VERSION "BMW i3 FlexRay custom draft v3"

NS_ :

BS_:

BU_: BMW_I3

CM_ "Draft DBC derived from BMW i3 FlexRay and PT-CAN logs. Address 27 was not observed in any uploaded segment. Signals below intentionally mix three classes: confirmed parse signals already used by CarState, state/proxy helpers useful for reverse engineering, and unresolved TX candidates kept for shadow-debug correlation.";

BO_ 21 LAT_STOCK_ANGLE_REQUEST_15: 17 BMW_I3
 SG_ LAT_STOCK_ANGLE_15_CYCLE_RAW : 0|8@1+ (1,0) [0|255] "" BMW_I3
 SG_ LAT_STOCK_ANGLE_15_WORD_1_2 : 8|16@1+ (1,0) [0|65535] "" BMW_I3
 SG_ LAT_STOCK_ANGLE_15_WORD_3_4 : 24|16@1+ (1,0) [0|65535] "" BMW_I3
 SG_ LAT_STOCK_ANGLE_15_WORD_5_6 : 40|16@1+ (1,0) [0|65535] "" BMW_I3
 SG_ LAT_STOCK_ANGLE_15_RAW : 56|16@1+ (1,0) [0|65535] "" BMW_I3
 SG_ LAT_STOCK_ANGLE_15_DEG_DRAFT : 56|16@1+ (0.011831,-387.55) [-720|720] "deg" BMW_I3
 SG_ LAT_STOCK_ANGLE_15_ICAN_48_OFFSET_TEST : 24|16@1+ (0.04395,-1098.75) [-720|720] "deg" BMW_I3
 SG_ LAT_STOCK_ANGLE_15_BRANCH_MARKER : 72|64@1+ (1,0) [0|18446744073709551615] "" BMW_I3
CM_ BO_ 21 "Stock angle-request candidate on the EDME-to-EPS side. Local route 58/59 analysis selects bytes 7..8 little-endian, not the I-CAN-hack 0x48 byte3..4 field: correlation against valid 0x33/src24 EPS angle is about +0.980 on route 58 and +0.929 on route 59. Treat only cycle byte0&0x3 == 0 or 2 plus bytes9..16 == FF as the real branch; the other branch is structural zero padding. Firmware TX is intentionally not enabled until the scheduler trigger is proven.";
CM_ SG_ 21 LAT_STOCK_ANGLE_15_RAW "Primary local angle-request candidate: raw = uint16_le(byte7, byte8). Observed near center around 32768; route-backed draft angle conversion is LAT_STOCK_ANGLE_15_DEG_DRAFT.";
CM_ SG_ 21 LAT_STOCK_ANGLE_15_DEG_DRAFT "Draft local fit from EDME/EPS routes 58 and 59 against valid 0x33 EPS_STEERING_ANGLE_BMW: angle_deg ~= raw * 0.011831 - 387.55. This is for analysis/openpilot target construction only and must be refined before closed-loop TX.";
CM_ SG_ 21 LAT_STOCK_ANGLE_15_ICAN_48_OFFSET_TEST "Reference-only I-CAN-hack 0x48 angle layout applied to 0x15 byte3..4. It is kept to compare against their formula, but local logs show byte7..8 is the stronger candidate.";
CM_ SG_ 21 LAT_STOCK_ANGLE_15_BRANCH_MARKER "Real 0x15 angle branch observed with bytes9..16 all 0xFF; zero branch must be ignored during correlation and TX reconstruction.";

BO_ 49 STEER_TORQUE: 17 BMW_I3
 SG_ STEER_TORQUE_CYCLE_RAW : 0|8@1+ (1,0) [0|255] "" BMW_I3
 SG_ STEER_TORQUE_RAW_WORD_A : 8|16@1+ (1,0) [0|65535] "" BMW_I3
 SG_ STEER_TORQUE_RAW_WORD_B : 24|16@1+ (1,0) [0|65535] "" BMW_I3
 SG_ STEER_TORQUE_RAW_WORD_C : 40|16@1+ (1,0) [0|65535] "" BMW_I3
 SG_ STEER_TORQUE_RAW_WORD_D : 56|16@1+ (1,0) [0|65535] "" BMW_I3
 SG_ DRIVER_STEER_TORQUE_BMW : 24|12@1+ (0.005,-10) [-10|10.475] "Nm" BMW_I3
 SG_ STEER_TORQUE_STATUS_RAW : 24|8@1+ (1,0) [0|255] "" BMW_I3
 CM_ BO_ 49 "Confirmed steering-torque helper. BMW-style driver torque lives in the 24|12 field and is valid on the cycle-0 subframe. CarState uses this path for steeringTorque/steeringPressed.";

BO_ 51 EPS_ANGLE: 17 BMW_I3
 SG_ EPS_ANGLE_CYCLE_RAW : 0|8@1+ (1,0) [0|255] "" BMW_I3
 SG_ EPS_ANGLE_RAW_WORD_A : 8|16@1+ (1,0) [0|65535] "" BMW_I3
 SG_ EPS_ANGLE_RAW_WORD_B : 24|16@1+ (1,0) [0|65535] "" BMW_I3
 SG_ EPS_ANGLE_RAW_WORD_C : 40|16@1+ (1,0) [0|65535] "" BMW_I3
 SG_ EPS_ANGLE_RAW_WORD_D : 56|16@1+ (1,0) [0|65535] "" BMW_I3
 SG_ EPS_STEERING_ANGLE_BMW : 24|16@1+ (0.042420980556,-1390.727380850223) [-465|465] "deg" BMW_I3
 CM_ BO_ 51 "FlexRay EPS angle frame. Raw steering angle lives in word B as bytes 3:4 little-endian and only the active subframes where byte0&0x3 is 0 or 2 carry angle content. Subframes 1 and 3 are structurally empty.";
CM_ SG_ 51 EPS_STEERING_ANGLE_BMW "Primary FlexRay EPS steering-angle candidate from raw word B at 24|16@1+ interpreted little-endian. Global refit against the legacy CAN steering angle on 0x302 across routes 0x401 and 0x402: angle_deg ~= raw_B * 0.042420980556 - 1390.727380850223. Apply only on active cycles 0/2; cycles 1/3 should be treated as empty subframes.";

BO_ 55 VEHICLE_SPEED_PROV: 17 BMW_I3
 SG_ VEHICLE_SPEED_CYCLE_RAW M : 0|2@1+ (1,0) [0|3] "" BMW_I3
 SG_ VEHICLE_SPEED_RAW_WORD_A : 8|16@1+ (1,0) [0|65535] "" BMW_I3
 SG_ VEHICLE_SPEED_RAW_WORD_B : 24|16@1+ (1,0) [0|65535] "" BMW_I3
 SG_ VEHICLE_SPEED_RAW_WORD_C : 40|16@1+ (1,0) [0|65535] "" BMW_I3
 SG_ VEHICLE_SPEED_RAW_WORD_D : 56|16@1+ (1,0) [0|65535] "" BMW_I3
 SG_ LONG_ACCEL_RAW m0 : 24|16@1+ (0.002,-65) [0|65535] "" BMW_I3
 SG_ VEHICLE_SPEED_BMW m3 : 24|16@1+ (0.015625,0) [0|65535] "kph" BMW_I3
 SG_ DRIVING_STATUS_BMW m3 : 44|2@1+ (1,0) [0|7] "" BMW_I3
CM_ BO_ 55 "Confirmed primary vehicle-speed source aligned with the BMW SP2018 multiplexed layout. CarState consumes the m3 vehicle-speed subframe directly for runtime vehicle speed.";

BO_ 56 DYNAMICS_YAW_PROV: 17 BMW_I3
 SG_ DYNAMICS_YAW_RAW_WORD_A : 8|16@1+ (1,0) [0|65535] "" BMW_I3
 SG_ DYNAMICS_YAW_RAW_WORD_B : 24|16@1+ (1,0) [0|65535] "" BMW_I3
 SG_ DYNAMICS_YAW_RAW_WORD_C : 40|16@1+ (1,0) [0|65535] "" BMW_I3
 SG_ DYNAMICS_YAW_RAW_WORD_D : 56|16@1+ (1,0) [0|65535] "" BMW_I3
 SG_ YAW_RATE_RAW_A : 8|16@1- (0.01,0) [-500|500] "deg/s" BMW_I3
 SG_ YAW_RATE_RAW_B : 24|16@1- (0.01,0) [-500|500] "deg/s" BMW_I3
 SG_ STEERING_ANGLE_PROXY_56_RAW : 88|16@1+ (1,0) [0|65535] "" BMW_I3
 SG_ STEERING_ANGLE_PROXY_56_DEG : 88|16@1+ (0.0260328634,-851.998806) [-720|720] "deg" BMW_I3
CM_ BO_ 56 "Confirmed vehicle-dynamics helper. Raw yaw fields remain useful for reverse-engineering and stock lateral comparison work. The late word at bytes 11..12 is kept only as a secondary steering-angle debug/support candidate now that frame 51 is promoted.";
CM_ SG_ 56 STEERING_ANGLE_PROXY_56_RAW "Secondary debug/support steering-angle proxy from route 00000402 fitting against PT-CAN 770. Keep for analysis only; no longer the primary steeringAngleDeg source.";
CM_ SG_ 56 STEERING_ANGLE_PROXY_56_DEG "Debug/support steering-angle estimate derived from STEERING_ANGLE_PROXY_56_RAW using the historical fit angle_deg ~= 0.0260328634 * raw56 - 851.998806. Not the primary steeringAngleDeg source anymore.";

BO_ 40 DRIVE_STATE: 17 BMW_I3
 SG_ DRIVE_STATE_CYCLE_COMPAT : 0|2@1+ (1,0) [0|3] "" BMW_I3
 SG_ DRIVE_STATE_RAW : 8|16@1+ (1,0) [0|65535] "" BMW_I3
  SG_ DRIVE_MODE_RAW : 24|8@1+ (1,0) [0|255] "" BMW_I3
 SG_ DRIVE_STATE_GEAR_M3_COMPAT : 24|4@1+ (1,0) [0|15] "" BMW_I3
 SG_ DRIVE_STATE_P_LOCKED_M3_COMPAT : 49|1@1+ (1,0) [0|1] "" BMW_I3
 SG_ DRIVE_STATE_KIND_BYTE_11 : 88|8@1+ (1,0) [0|255] "" BMW_I3
 SG_ DRIVE_STATE_KIND_BYTE_14 : 112|8@1+ (1,0) [0|255] "" BMW_I3
CM_ BO_ 40 "Production drive-state frame. Cross-check against dynm BMW SP2018 FlexRay DBC shows this frame is the closest local match to their maybe_gear_switch frame, and current i3 routes support using its cycle_count plus the byte-11/byte-14 discriminator path as the primary FlexRay gear source in CarState.";

BO_ 44 LAT_STOCK_TORQUE_CONTROL_44: 17 BMW_I3
 SG_ LAT_STOCK_TORQUE_44_CYCLE_COUNT : 7|8@0+ (1,0) [0|255] "" BMW_I3
 SG_ LAT_STOCK_TORQUE_44_CHECKSUM_1 : 15|8@0+ (1,0) [0|255] "" BMW_I3
 SG_ LAT_STOCK_TORQUE_44_COUNTER_1 : 19|4@0+ (1,0) [0|15] "" BMW_I3
 SG_ LAT_STOCK_TORQUE_44_CONST_F_1 : 23|4@0+ (1,0) [0|15] "" BMW_I3
 SG_ LAT_STOCK_TORQUE_44_CONST_D0 : 31|8@0+ (1,0) [0|255] "" BMW_I3
 SG_ LAT_STOCK_TORQUE_44_CONST_E7 : 39|8@0+ (1,0) [0|255] "" BMW_I3
 SG_ LAT_STOCK_TORQUE_44_BYTE_5_BE : 47|8@0+ (1,0) [0|255] "" BMW_I3
 SG_ LAT_STOCK_TORQUE_44_BYTE_6 : 48|8@1+ (1,0) [0|255] "" BMW_I3
 SG_ LAT_STOCK_TORQUE_44_NIBBLE_7 : 59|4@0+ (1,0) [0|7] "" BMW_I3
 SG_ LAT_STOCK_TORQUE_44_MODE : 67|4@0+ (1,0) [0|15] "" BMW_I3
 SG_ LAT_STOCK_TORQUE_44_REQUEST_1 : 68|1@0+ (1,0) [0|1] "" BMW_I3
 SG_ LAT_STOCK_TORQUE_44_CHECKSUM_2 : 79|8@0+ (1,0) [0|255] "" BMW_I3
 SG_ LAT_STOCK_TORQUE_44_COUNTER_2 : 83|4@0+ (1,0) [0|15] "" BMW_I3
 SG_ LAT_STOCK_TORQUE_44_CONST_F_2 : 87|4@0+ (1,0) [0|15] "" BMW_I3
 SG_ LAT_STOCK_TORQUE_44_RAW : 104|16@1- (1,0) [-32768|32767] "" BMW_I3
 SG_ LAT_STOCK_TORQUE_44_ALT_WORD_10_11 : 80|16@1+ (1,0) [0|65535] "" BMW_I3
 SG_ LAT_STOCK_TORQUE_44_ALT_WORD_12_13 : 96|16@1- (1,0) [-32768|32767] "" BMW_I3
 SG_ LAT_STOCK_TORQUE_44_ALT_WORD_14_15 : 112|16@1- (1,0) [-32768|32767] "" BMW_I3
 SG_ LAT_STOCK_TORQUE_44_ICAN_HACK_NM : 88|12@1+ (0.005,-10) [-10|10.475] "Nm" BMW_I3
 SG_ LAT_STOCK_TORQUE_44_MODE_COPY : 103|4@0+ (1,0) [0|15] "" BMW_I3
 SG_ LAT_STOCK_TORQUE_44_CONST_FF_1 : 111|8@0+ (1,0) [0|255] "" BMW_I3
 SG_ LAT_STOCK_TORQUE_44_CONST_FF_2 : 119|8@0+ (1,0) [0|255] "" BMW_I3
 SG_ LAT_STOCK_TORQUE_44_CONST_F_3 : 123|4@0+ (1,0) [0|15] "" BMW_I3
 SG_ LAT_STOCK_TORQUE_44_REQUEST_2 : 125|2@0+ (1,0) [0|3] "" BMW_I3
 SG_ LAT_STOCK_TORQUE_44_LKA_STATE : 131|4@0+ (1,0) [0|15] "" BMW_I3
 SG_ LAT_STOCK_TORQUE_44_REQUEST_3 : 132|1@0+ (1,0) [0|1] "" BMW_I3
CM_ BO_ 44 "Stock lateral torque/control candidate on the vehicle-side companion stream. Route 58/59 TJA-window analysis points to bytes 13..14 signed little-endian as the strongest local equivalent to 0x33/src1 steering output. Firmware injection follows the I-CAN-hack raw override model: trigger 0x42, target 0x44, cycle mask 0x01, base 0, copy payload bytes 1..16, direction FR3, then update only the FlexRay header cycle/count CRC. Host/openpilot must compute payload CRCs byte1=crc8(byte2..8, init 0xA4) and byte9=crc8(byte10..16, init 0xDC).";
CM_ SG_ 44 LAT_STOCK_TORQUE_44_RAW "Primary local torque/control-like value: raw = int16_le(byte13, byte14). Correlation against 0x33/src1 bytes 3..4 inside managed TJA windows was about +0.847 on route 58 and +0.916 on route 59.";
CM_ SG_ 44 LAT_STOCK_TORQUE_44_ALT_WORD_10_11 "Secondary debug word from bytes 10..11. Keep only for comparison while reconstructing the full 0x44 payload.";
CM_ SG_ 44 LAT_STOCK_TORQUE_44_ALT_WORD_12_13 "Secondary debug word from bytes 12..13. It correlates less consistently than bytes 13..14 and is not the selected torque value.";
CM_ SG_ 44 LAT_STOCK_TORQUE_44_ALT_WORD_14_15 "Secondary debug word from bytes 14..15. Keep only for comparison while reconstructing the full 0x44 payload.";
CM_ SG_ 44 LAT_STOCK_TORQUE_44_ICAN_HACK_NM "Reference layout from I-CAN-hack pico-flexray 0x44 EPS_CONTROL torque field: 12-bit unsigned at byte11/bit88, factor 0.005, offset -10 Nm. Included as a cross-check, not selected over the local b13..14 route fit.";
CM_ SG_ 44 LAT_STOCK_TORQUE_44_CHECKSUM_1 "Application CRC for the first 0x44 payload block. Host must set this to crc8(payload bytes 2..8, init 0xA4); firmware raw override does not recalculate it.";
CM_ SG_ 44 LAT_STOCK_TORQUE_44_CHECKSUM_2 "Application CRC for the second 0x44 payload block. Host must set this to crc8(payload bytes 10..16, init 0xDC); firmware raw override does not recalculate it.";
CM_ SG_ 44 LAT_STOCK_TORQUE_44_MODE "I-CAN-hack EPS_CONTROL torque mode field. Their script uses 2 when active, mostly 14 otherwise.";
CM_ SG_ 44 LAT_STOCK_TORQUE_44_MODE_COPY "Mirror of LAT_STOCK_TORQUE_44_MODE in the I-CAN-hack EPS_CONTROL layout.";
CM_ SG_ 44 LAT_STOCK_TORQUE_44_LKA_STATE "I-CAN-hack EPS_CONTROL LKA state field. Observed/scripted behavior ramps through 0..14 on engage/disengage and typically stays around 5..9 while active.";
CM_ SG_ 44 LAT_STOCK_TORQUE_44_REQUEST_2 "I-CAN-hack EPS_CONTROL request state: 1 inactive, 2 active.";
CM_ SG_ 44 LAT_STOCK_TORQUE_44_REQUEST_3 "I-CAN-hack EPS_CONTROL request bit. Their script sets it to 1 only while not ramping up/down and active.";
VAL_ 44 LAT_STOCK_TORQUE_44_REQUEST_2 1 "INACTIVE" 2 "ACTIVE";

BO_ 60 LAT_STOCK_TX_TRIGGER_CANDIDATE: 17 BMW_I3
 SG_ LAT_STOCK_TRIGGER_PHASE_BYTE_0 : 0|8@1+ (1,0) [0|255] "" BMW_I3
 SG_ LAT_STOCK_TRIGGER_SUBFRAME_LSB : 0|2@1+ (1,0) [0|3] "" BMW_I3
 SG_ LAT_STOCK_TRIGGER_CMD_PHASE : 1|5@1+ (1,0) [0|31] "" BMW_I3
CM_ BO_ 60 "Primary SAS-side predecessor/trigger for the stock lateral burst on the i3. Latest route work now treats frame 96 as the active payload candidate. Frame 60 itself remains structurally near-empty outside byte0, so treat it as the scheduler/trigger half of the burst rather than the analog steering payload.";
CM_ SG_ 60 LAT_STOCK_TRIGGER_PHASE_BYTE_0 "Raw scheduler byte for the SAS-side lateral burst. This remains the practical trigger byte for firmware-aligned injection work.";
CM_ SG_ 60 LAT_STOCK_TRIGGER_SUBFRAME_LSB "Low two bits of frame-60 byte0. Useful when reconstructing the four-subframe burst order observed in the SAS 20 ms lateral scheduler.";
CM_ SG_ 60 LAT_STOCK_TRIGGER_CMD_PHASE "Derived command-phase view of frame-60 byte0 (byte0 >> 1). Keep as a coarse scheduler helper while the real command stays phase-local on frame 96.";

BO_ 72 LAT_STOCK_FRAME_72_CANDIDATE: 17 BMW_I3
 SG_ LAT_STOCK_72_BYTE_0 : 0|8@1+ (1,0) [0|255] "" BMW_I3
 SG_ LAT_STOCK_72_CYCLE_COUNT : 0|8@1+ (1,0) [0|255] "" BMW_I3
 SG_ LAT_STOCK_72_BYTE_1 : 8|8@1+ (1,0) [0|255] "" BMW_I3
 SG_ LAT_STOCK_72_CRC1 : 8|8@1+ (1,0) [0|255] "" BMW_I3
 SG_ LAT_STOCK_72_BYTE_2 : 16|8@1+ (1,0) [0|255] "" BMW_I3
 SG_ LAT_STOCK_72_CNT1 : 20|4@1+ (1,0) [0|15] "" BMW_I3
 SG_ LAT_STOCK_72_ALWAYS_0X9 : 16|4@1+ (1,0) [0|15] "" BMW_I3
 SG_ LAT_STOCK_72_BYTE_3 : 24|8@1+ (1,0) [0|255] "" BMW_I3
 SG_ LAT_STOCK_72_BYTE_4 : 32|8@1+ (1,0) [0|255] "" BMW_I3
 SG_ LAT_STOCK_72_STEERING_ANGLE_REQ : 24|16@1+ (1,0) [0|65535] "" BMW_I3
 SG_ LAT_STOCK_72_BYTE_5 : 40|8@1+ (1,0) [0|255] "" BMW_I3
 SG_ LAT_STOCK_72_BYTE_6 : 48|8@1+ (1,0) [0|255] "" BMW_I3
 SG_ LAT_STOCK_72_STEER_TORQUE_REQ : 40|16@1+ (1,0) [0|65535] "" BMW_I3
 SG_ LAT_STOCK_72_BYTE_7 : 56|8@1+ (1,0) [0|255] "" BMW_I3
 SG_ LAT_STOCK_72_TJA_READY : 56|8@1+ (1,0) [0|255] "" BMW_I3
 SG_ LAT_STOCK_72_BYTE_8 : 64|8@1+ (1,0) [0|255] "" BMW_I3
 SG_ LAT_STOCK_72_ASSIST_MODE : 64|8@1+ (1,0) [0|255] "" BMW_I3
 SG_ LAT_STOCK_72_BYTE_9 : 72|8@1+ (1,0) [0|255] "" BMW_I3
 SG_ LAT_STOCK_72_WAYBACK_EN1_LANE_KEEPING_TRIGGER : 72|8@1+ (1,0) [0|255] "" BMW_I3
 SG_ LAT_STOCK_72_BYTE_10 : 80|8@1+ (1,0) [0|255] "" BMW_I3
 SG_ LAT_STOCK_72_LANE_KEEPING_TRIGGERED : 80|8@1+ (1,0) [0|255] "" BMW_I3
 SG_ LAT_STOCK_72_BYTE_11 : 88|8@1+ (1,0) [0|255] "" BMW_I3
 SG_ LAT_STOCK_72_LIKE_ASSIST_TORQUE_RESERVE : 88|8@1+ (1,0) [0|255] "" BMW_I3
 SG_ LAT_STOCK_72_BYTE_12 : 96|8@1+ (1,0) [0|255] "" BMW_I3
 SG_ LAT_STOCK_72_BYTE_13 : 104|8@1+ (1,0) [0|255] "" BMW_I3
 SG_ LAT_STOCK_72_BYTE_14 : 112|8@1+ (1,0) [0|255] "" BMW_I3
 SG_ LAT_STOCK_72_CONSTANTS : 96|26@1+ (1,0) [0|262143] "" BMW_I3
 SG_ LAT_STOCK_72_WAYBACK_EN_2 : 114|2@1+ (1,0) [0|3] "" BMW_I3
 SG_ LAT_STOCK_72_STEERING_ENGAGED : 116|4@1+ (1,0) [0|15] "" BMW_I3
 SG_ LAT_STOCK_72_BYTE_15 : 120|8@1+ (1,0) [0|255] "" BMW_I3
 SG_ LAT_STOCK_72_BYTE_16 : 128|8@1+ (1,0) [0|255] "" BMW_I3
CM_ BO_ 72 "Raw stock frame-72 candidate, reintroduced for parameter-by-parameter comparison against the SP2018 72-byte layout. Current fixed synthetic blocks: cycle_count = 0x00, crc1 = 0x00 with real final CRC to be computed later outside the DBC, cnt1 = 0x00, always_0x9 placeholder = 0xF, steering_angle_req placeholder = 0x0000, steer_torque_req placeholder = 0xFFFF, TJA_ready placeholder = 0xFF, assist_mode placeholder = 0xE0, wayback_en1_lane_keeping_trigger placeholder = 0xFF, lane_keeping_triggered placeholder = 0xFF, like_assist_torque_reserve placeholder = 0xFF, constants placeholder = 0x3FFFF, wayback_en_2 placeholder = 0x3, steering_engaged placeholder = 0xF. For blocks 3-14, firmware currently preserves the live OEM payload bytes from the cached 72 template.";
CM_ SG_ 72 LAT_STOCK_72_CYCLE_COUNT "Block 1 candidate on local frame 72. Current synthetic decision: use a fixed value of 0x00 when building a local 72 frame, matching the simpler dynm-style approach instead of waiting on OEM live timing.";
CM_ SG_ 72 LAT_STOCK_72_CRC1 "Block 2 candidate on local frame 72. Current synthetic decision: keep this DBC-visible crc1 field at 0x00 and compute any real final CRC later outside the DBC, dynm-style.";
CM_ SG_ 72 LAT_STOCK_72_CNT1 "Block 3 candidate on local frame 72 in the same positional slot as SP2018 cnt1. Current synthetic decision: fix it to 0x00, matching SMNOGAR/dynm builder behavior.";
CM_ SG_ 72 LAT_STOCK_72_ALWAYS_0X9 "Block 4 candidate on local frame 72 in the same positional slot as SP2018 always_0x9. Placeholder decision in DBC/controller: set to 0xF if synthesized locally. Firmware currently preserves the live OEM high nibble of byte2 from the cached 72 template, so the placeholder is not the final bus value.";
CM_ SG_ 72 LAT_STOCK_72_STEERING_ANGLE_REQ "Block 5 candidate in the same positional slot as SP2018 steering_angle_req. Placeholder decision in DBC/controller: set to 0x0000 if synthesized locally. Firmware currently preserves the live OEM bytes 3:4 from the cached 72 template, so this placeholder is not the final bus value.";
CM_ SG_ 72 LAT_STOCK_72_STEER_TORQUE_REQ "Block 6 candidate in the same positional slot as SP2018 steer_torque_req. Placeholder decision in DBC/controller: set to 0xFFFF if synthesized locally. Firmware currently preserves the live OEM bytes 5:6 from the cached 72 template, so this placeholder is not the final bus value.";
CM_ SG_ 72 LAT_STOCK_72_TJA_READY "Block 7 candidate in the same positional slot as SP2018 TJA_ready. Placeholder decision in DBC/controller: set to 0xFF if synthesized locally. Firmware currently preserves the live OEM byte7 from the cached 72 template, so this placeholder is not the final bus value.";
CM_ SG_ 72 LAT_STOCK_72_ASSIST_MODE "Block 8 candidate in the same positional slot as SP2018 assist_mode. Placeholder decision in DBC/controller: set to 0xE0 if synthesized locally. Firmware currently preserves the live OEM byte8 from the cached 72 template, so this placeholder is not the final bus value.";
CM_ SG_ 72 LAT_STOCK_72_WAYBACK_EN1_LANE_KEEPING_TRIGGER "Block 9 candidate in the same positional slot as SP2018 wayback_en1_lane_keeping_trigger. Placeholder decision in DBC/controller: set to 0xFF if synthesized locally. Firmware currently preserves the live OEM byte9 from the cached 72 template, so this placeholder is not the final bus value.";
CM_ SG_ 72 LAT_STOCK_72_LANE_KEEPING_TRIGGERED "Block 10 candidate in the same positional slot as SP2018 lane_keeping_triggered. Placeholder decision in DBC/controller: set to 0xFF if synthesized locally. Firmware currently preserves the live OEM byte10 from the cached 72 template, so this placeholder is not the final bus value.";
CM_ SG_ 72 LAT_STOCK_72_LIKE_ASSIST_TORQUE_RESERVE "Block 11 candidate in the same positional slot as SP2018 like_assist_torque_reserve. Placeholder decision in DBC/controller: set to 0xFF if synthesized locally. Firmware currently preserves the live OEM byte11 from the cached 72 template, so this placeholder is not the final bus value.";
CM_ SG_ 72 LAT_STOCK_72_CONSTANTS "Block 12 candidate in the same positional slot as SP2018 constants. Placeholder decision in DBC/controller: set to 0x3FFFF if synthesized locally. Firmware currently preserves the live OEM bytes 12:14 (including the low 2 bits of byte14) from the cached 72 template, so this placeholder is not the final bus value.";
CM_ SG_ 72 LAT_STOCK_72_WAYBACK_EN_2 "Block 13 candidate in the same positional slot as SP2018 wayback_en_2. Placeholder decision in DBC/controller: set to 0x3 if synthesized locally. Firmware already preserves the live OEM byte14 from the cached 72 template, so this placeholder is not the final bus value.";
CM_ SG_ 72 LAT_STOCK_72_STEERING_ENGAGED "Block 14 candidate in the same positional slot as SP2018 steering_engaged. Placeholder decision in DBC/controller: set to 0xF if synthesized locally. Firmware already preserves the live OEM byte14 from the cached 72 template, so this placeholder is not the final bus value.";

BO_ 43 CHASSIS_STATE_CANDIDATE: 17 BMW_I3
 SG_ CHASSIS_STATE_A : 8|16@1+ (1,0) [0|65535] "" BMW_I3
 SG_ CHASSIS_STATE_B : 24|16@1+ (1,0) [0|65535] "" BMW_I3
 CM_ SG_ 43 CHASSIS_STATE_A "Experimental secondary dynamic-state frame. It follows some longitudinal phase changes, but remains too weak and indirect for stock command use.";

BO_ 63 LONG_STATE_HELPER_D: 17 BMW_I3
 SG_ LONG_STATE_HELPER_D_WORD_A : 8|16@1+ (1,0) [0|65535] "" BMW_I3
 SG_ LONG_STATE_HELPER_D_WORD_B : 24|16@1+ (1,0) [0|65535] "" BMW_I3
 SG_ LONG_STATE_HELPER_D_WORD_C : 40|16@1+ (1,0) [0|65535] "" BMW_I3
 SG_ LONG_STATE_HELPER_D_WORD_D : 56|16@1+ (1,0) [0|65535] "" BMW_I3
 CM_ BO_ 63 "Raw helper frame for longitudinal state closure. Keep read-only; do not treat as a direct accel command.";

BO_ 93 ACC_TJA_OLD_ROUTE_HELPER_A: 17 BMW_I3
 SG_ ACC_TJA_OLD_A_CYCLE : 0|8@1+ (1,0) [0|255] "" BMW_I3
 SG_ LONG_STATE_HELPER_A_WORD_A : 8|16@1+ (1,0) [0|65535] "" BMW_I3
 SG_ LONG_STATE_HELPER_A_WORD_B : 24|16@1+ (1,0) [0|65535] "" BMW_I3
 SG_ LONG_STATE_HELPER_A_WORD_C : 40|16@1+ (1,0) [0|65535] "" BMW_I3
 SG_ LONG_STATE_HELPER_A_WORD_D : 56|16@1+ (1,0) [0|65535] "" BMW_I3
 SG_ ACC_TJA_OLD_A_WORD_A : 8|16@1+ (1,0) [0|65535] "" BMW_I3
 SG_ ACC_TJA_OLD_A_WORD_B : 24|16@1+ (1,0) [0|65535] "" BMW_I3
 SG_ ACC_TJA_OLD_A_WORD_C : 40|16@1+ (1,0) [0|65535] "" BMW_I3
 SG_ ACC_TJA_OLD_A_WORD_D : 56|16@1+ (1,0) [0|65535] "" BMW_I3
 SG_ ACC_TJA_OLD_STATE_MAIN_A : 40|16@1+ (1,0) [0|65535] "" BMW_I3
 CM_ BO_ 93 "Experimental helper from legacy multi-segment TJA routes 00000054/55/56. This src23 frame repeatedly changed around ACC/TJA/stalk command windows and is kept as a raw helper only for old-route correlation.";

BO_ 97 ACC_TJA_OLD_ROUTE_HELPER_B: 17 BMW_I3
 SG_ ACC_TJA_OLD_B_CYCLE : 0|8@1+ (1,0) [0|255] "" BMW_I3
 SG_ ACC_TJA_OLD_B_WORD_A : 8|16@1+ (1,0) [0|65535] "" BMW_I3
 SG_ ACC_TJA_OLD_B_WORD_B : 24|16@1+ (1,0) [0|65535] "" BMW_I3
 SG_ ACC_TJA_OLD_B_WORD_C : 40|16@1+ (1,0) [0|65535] "" BMW_I3
 SG_ ACC_TJA_OLD_B_WORD_D : 56|16@1+ (1,0) [0|65535] "" BMW_I3
 SG_ ACC_TJA_OLD_STALK_MAIN_A : 8|16@1+ (1,0) [0|65535] "" BMW_I3
 SG_ ACC_TJA_OLD_STALK_MAIN_B : 24|16@1+ (1,0) [0|65535] "" BMW_I3
 CM_ BO_ 97 "Experimental helper from legacy multi-segment TJA routes 00000054/55/56. This src23 frame is one of the strongest recurring candidates for ACC/TJA/stalk command state and is exposed raw for old-route analysis.";

BO_ 102 COLUMN_SWITCH_CANDIDATE: 17 BMW_I3
 SG_ COLUMN_SWITCH_WORD_A : 8|16@1+ (1,0) [0|65535] "" BMW_I3
 SG_ COLUMN_SWITCH_WORD_B : 24|16@1+ (1,0) [0|65535] "" BMW_I3
 SG_ COLUMN_SWITCH_WORD_C : 40|16@1+ (1,0) [0|65535] "" BMW_I3
 SG_ COLUMN_SWITCH_WORD_D : 56|16@1+ (1,0) [0|65535] "" BMW_I3
 CM_ BO_ 102 "Experimental column-switch / indicator candidate. In the parked command-isolation route, this frame changed clearly during right/left indicator windows and also moved with some ACC/TJA button presses. Treat as a likely steering-column input frame rather than pure ADAS state.";

BO_ 110 ACC_TJA_OLD_ROUTE_HELPER_C: 17 BMW_I3
 SG_ ACC_TJA_OLD_C_CYCLE : 0|8@1+ (1,0) [0|255] "" BMW_I3
 SG_ ACC_TJA_OLD_C_WORD_A : 8|16@1+ (1,0) [0|65535] "" BMW_I3
 SG_ ACC_TJA_OLD_C_WORD_B : 24|16@1+ (1,0) [0|65535] "" BMW_I3
 SG_ ACC_TJA_OLD_C_WORD_C : 40|16@1+ (1,0) [0|65535] "" BMW_I3
 SG_ ACC_TJA_OLD_C_WORD_D : 56|16@1+ (1,0) [0|65535] "" BMW_I3
 CM_ BO_ 110 "Experimental helper from legacy multi-segment TJA routes 00000054/55/56. This src23 frame moved with speed-stalk and ACC transitions often enough to warrant a raw helper block.";

BO_ 106 ACC_STALK_TJA_CANDIDATE_A: 17 BMW_I3
 SG_ ACC_STALK_TJA_WORD_A : 8|16@1+ (1,0) [0|65535] "" BMW_I3
 SG_ ACC_STALK_TJA_WORD_B : 24|16@1+ (1,0) [0|65535] "" BMW_I3
 SG_ ACC_STALK_TJA_WORD_C : 40|16@1+ (1,0) [0|65535] "" BMW_I3
 SG_ ACC_STALK_TJA_WORD_D : 56|16@1+ (1,0) [0|65535] "" BMW_I3
 CM_ BO_ 106 "Experimental ACC/TJA candidate from TJA and parked command-isolation routes. Changed coherently around SET, RES, ACC, TJA, speed-stalk increment/decrement, distance-button, and ACC off windows. Byte pair around bits 24..39 stayed stable enough for comparison across sessions, but no clean bit-level interpretation is confirmed yet.";

BO_ 112 ACC_STALK_TJA_CANDIDATE_B: 17 BMW_I3
 SG_ ACC_STALK_TJA_B_WORD_A : 8|16@1+ (1,0) [0|65535] "" BMW_I3
 SG_ ACC_STALK_TJA_B_WORD_B : 24|16@1+ (1,0) [0|65535] "" BMW_I3
 SG_ ACC_STALK_TJA_B_WORD_C : 40|16@1+ (1,0) [0|65535] "" BMW_I3
 SG_ ACC_STALK_TJA_B_WORD_D : 56|16@1+ (1,0) [0|65535] "" BMW_I3
 SG_ LAT_STOCK_MAIN_BYTE_0 : 0|8@1+ (1,0) [0|255] "" BMW_I3
 SG_ LAT_STOCK_MAIN_BYTE_1 : 8|8@1+ (1,0) [0|255] "" BMW_I3
 SG_ LAT_STOCK_MAIN_WORD_A : 8|16@1+ (1,0) [0|65535] "" BMW_I3
 SG_ LAT_STOCK_MAIN_WORD_B : 24|16@1+ (1,0) [0|65535] "" BMW_I3
 SG_ LAT_STOCK_MAIN_WORD_C : 40|16@1+ (1,0) [0|65535] "" BMW_I3
 SG_ LAT_STOCK_MAIN_WORD_D : 56|16@1+ (1,0) [0|65535] "" BMW_I3
 SG_ LAT_STOCK_MAIN_BYTE_5 : 40|8@1+ (1,0) [0|255] "" BMW_I3
 SG_ LAT_STOCK_ACTIVE_HINT : 45|1@1+ (1,0) [0|1] "" BMW_I3
CM_ BO_ 112 "Primary lateral RX/state helper. Confirmed on historical routes 00000054 and 00000055 and reinforced by managed-TJA route 00000176. Historical logs exposed it on src24; modern dual-FlexRay logging exposes the same frame on src1. It changes cleanly between manual driving, ACC-base, and TJA-assisted steering windows and is the best current candidate for reverse-engineering stock lateral control state/content. Byte5 bit5 is the strongest live discriminator: off/manual tends to set the bit, assisted steering tends to clear it. CarState now uses this as the live stock_lat_active_hint gate before trusting the phase-local 96 direction hint.";
CM_ SG_ 112 LAT_STOCK_MAIN_BYTE_5 "Best current live assisted-steering state discriminator. Bit5 set tends to mean manual/off; bit5 clear tends to mean assisted/TJA-active. CarState uses this to gate the phase-local 96 direction hint.";
CM_ SG_ 112 LAT_STOCK_ACTIVE_HINT "Derived boolean helper from LAT_STOCK_MAIN_BYTE_5 bit5. 1 means the stock lateral system appears active enough to trust 96 direction hints; 0 means suppress direction to unknown.";

BO_ 116 ACC_STALK_TJA_CANDIDATE_C: 17 BMW_I3
 SG_ ACC_STALK_TJA_C_WORD_A : 8|16@1+ (1,0) [0|65535] "" BMW_I3
 SG_ ACC_STALK_TJA_C_WORD_B : 24|16@1+ (1,0) [0|65535] "" BMW_I3
 SG_ ACC_STALK_TJA_C_WORD_C : 40|16@1+ (1,0) [0|65535] "" BMW_I3
 SG_ ACC_STALK_TJA_C_WORD_D : 56|16@1+ (1,0) [0|65535] "" BMW_I3
 SG_ LAT_STOCK_SUPPORT_WORD_A : 8|16@1+ (1,0) [0|65535] "" BMW_I3
 SG_ LAT_STOCK_SUPPORT_WORD_B : 24|16@1+ (1,0) [0|65535] "" BMW_I3
 SG_ LAT_STOCK_SUPPORT_WORD_C : 40|16@1+ (1,0) [0|65535] "" BMW_I3
 SG_ LAT_STOCK_SUPPORT_WORD_D : 56|16@1+ (1,0) [0|65535] "" BMW_I3
 SG_ LAT_STOCK_SUPPORT_BYTE_1 : 8|8@1+ (1,0) [0|255] "" BMW_I3
 SG_ LAT_STOCK_SUPPORT_BYTE_2 : 16|8@1+ (1,0) [0|255] "" BMW_I3
 SG_ LAT_STOCK_SUPPORT_BYTE_5 : 40|8@1+ (1,0) [0|255] "" BMW_I3
CM_ BO_ 116 "Secondary lateral RX/state helper. Confirmed on historical routes 00000054 and 00000055, present on the modern interface in route 000000b3, and strengthened by managed-TJA route 00000176. Historical logs exposed it on src23; modern dual-FlexRay logging exposes the same frame on src1. It tracks the same assisted-steering phases as 112 and is the best current secondary helper for stock lateral command/echo analysis. Byte5 is not yet a standalone boolean, but it moves through stable phase families alongside 112 and is logged as support evidence for the live stock_lat_active_hint path.";
CM_ SG_ 116 LAT_STOCK_SUPPORT_BYTE_5 "Secondary state-support byte for stock lateral activity. Not yet a standalone boolean, but it moves through stable phase families alongside frame 112 and is useful as corroborating evidence when validating assisted-steering windows.";

BO_ 124 ACC_STALK_TJA_CANDIDATE_D: 17 BMW_I3
 SG_ ACC_STALK_TJA_D_WORD_A : 8|16@1+ (1,0) [0|65535] "" BMW_I3
 SG_ ACC_STALK_TJA_D_WORD_B : 24|16@1+ (1,0) [0|65535] "" BMW_I3
 SG_ ACC_STALK_TJA_D_WORD_C : 40|16@1+ (1,0) [0|65535] "" BMW_I3
 SG_ ACC_STALK_TJA_D_WORD_D : 56|16@1+ (1,0) [0|65535] "" BMW_I3
 CM_ BO_ 124 "Experimental ACC/TJA candidate from TJA and parked command-isolation routes. Strongly correlated with SET, RES, ACC, TJA, speed-stalk increment/decrement, distance-button, and ACC off. This frame is a priority candidate for future bit-level extraction of ACC/TJA state.";

BO_ 131 LAT_TJA_COMMAND_CANDIDATE: 17 BMW_I3
 SG_ LAT_TJA_CYCLE : 0|8@1+ (1,0) [0|255] "" BMW_I3
 SG_ LAT_TJA_BYTE_1 : 8|8@1+ (1,0) [0|255] "" BMW_I3
 SG_ LAT_TJA_BYTE_2 : 16|8@1+ (1,0) [0|255] "" BMW_I3
 SG_ LAT_TJA_BYTE_3 : 24|8@1+ (1,0) [0|255] "" BMW_I3
 SG_ LAT_TJA_BYTE_4 : 32|8@1+ (1,0) [0|255] "" BMW_I3
 SG_ LONG_TARGET_U_83 : 24|16@1+ (1,0) [0|65535] "" BMW_I3
 SG_ LONG_TARGET_SPEED_EST_83 : 24|16@1+ (0.047815,-1460.510) [0|300] "kph" BMW_I3
 SG_ LAT_TJA_BYTE_5 : 40|8@1+ (1,0) [0|255] "" BMW_I3
 SG_ LAT_TJA_BYTE_6 : 48|8@1+ (1,0) [0|255] "" BMW_I3
 SG_ LAT_TJA_BYTE_7 : 56|8@1+ (1,0) [0|255] "" BMW_I3
 SG_ LAT_TJA_BYTE_8 : 64|8@1+ (1,0) [0|255] "" BMW_I3
 SG_ LAT_TJA_GATE_BYTE_5 : 40|8@1+ (1,0) [0|255] "" BMW_I3
 SG_ LAT_TJA_GATE_BYTE_6 : 48|8@1+ (1,0) [0|255] "" BMW_I3
 SG_ LAT_TJA_GATE_VALID : 46|1@1+ (1,0) [0|1] "" BMW_I3
 SG_ LAT_TJA_DIR_RULE_B1 : 8|8@1+ (1,0) [0|255] "" BMW_I3
 SG_ LAT_TJA_DIR_RULE_B3 : 24|8@1+ (1,0) [0|255] "" BMW_I3
CM_ BO_ 131 "Mixed stock ADAS state/command frame on src0. Current route-backed work treats bytes 3:4 little-endian as the active stock longitudinal target-like field, not as a lateral-angle request. Bytes0/1/2/7/8 are live OEM structural or coded bytes and should be copied through from the real bus template. Bytes5/6 should normally be sent from the host as the active gate 0x80/0x02. Within the managed longitudinal branch, byte3 behaves like an analog modular value, byte4 counts byte3 wrap events, and the combined word at bytes 3:4 little-endian gives the best current stock-compatible target-speed-like value u = byte3 + 256*byte4. Byte1 remains unresolved and should currently be preserved from the OEM frame rather than synthesized.";
CM_ SG_ 131 LAT_TJA_CYCLE "Live OEM cycle/phase byte. Do not synthesize a static value; copy it from the cached real-bus 0x83 template before injection.";
CM_ SG_ 131 LAT_TJA_BYTE_1 "Live OEM unresolved coded byte. Current analysis does not support treating it as analog steering or a simple CRC/checksum, so preserve it from the cached real-bus 0x83 template before injection.";
CM_ SG_ 131 LAT_TJA_BYTE_2 "Live OEM cyclic byte. In active TJA it rolls 0xF0..0xFE with no observed exceptions on validated routes; copy it from the cached real-bus 0x83 template before injection.";
CM_ SG_ 131 LAT_TJA_BYTE_3 "Current best analog stock longitudinal candidate. Treat this as the low byte of the internal target-speed-like value only when paired with LAT_TJA_BYTE_4.";
CM_ SG_ 131 LAT_TJA_BYTE_4 "Slow wrap counter for LAT_TJA_BYTE_3. It increments on byte3 high-to-low wraps (255->0) and decrements on low-to-high wraps (0->255), giving u = byte3 + 256*byte4.";
CM_ SG_ 131 LONG_TARGET_U_83 "Debug-only stock longitudinal target-like value reconstructed as bytes 3:4 little-endian, i.e. u = byte3 + 256*byte4.";
CM_ SG_ 131 LONG_TARGET_SPEED_EST_83 "Debug-only speed estimate from LONG_TARGET_U_83 using the current best cross-route-compatible fit target_speed_kph ~= 0.047815 * u - 1460.510. Use for analysis only, not as a safety-critical actuation law.";
CM_ SG_ 131 LAT_TJA_BYTE_7 "Live OEM structural byte. Do not synthesize a static value; copy it from the cached real-bus 0x83 template before injection.";
CM_ SG_ 131 LAT_TJA_BYTE_8 "Live OEM structural byte. Do not synthesize a static value; copy it from the cached real-bus 0x83 template before injection.";
CM_ SG_ 131 LAT_TJA_GATE_BYTE_5 "Active TJA gate byte. Default host value should be 0x80.";
CM_ SG_ 131 LAT_TJA_GATE_BYTE_6 "Active TJA gate byte. Default host value should be 0x02.";
CM_ SG_ 131 LAT_TJA_GATE_VALID "Debug helper: true when byte5=0x80 and byte6=0x02.";
VAL_ 131 LAT_TJA_GATE_BYTE_5 0 "OFF_GATE" 128 "TJA_ACTIVE_DEFAULT" 131 "ALT_ACTIVE_401_ONLY";
VAL_ 131 LAT_TJA_GATE_BYTE_6 2 "TJA_ACTIVE_DEFAULT" 14 "OFF_GATE";

BO_ 135 ACC_TJA_OLD_ROUTE_HELPER_E: 17 BMW_I3
 SG_ ACC_TJA_OLD_E_CYCLE : 0|8@1+ (1,0) [0|255] "" BMW_I3
 SG_ ACC_TJA_OLD_E_WORD_A : 8|16@1+ (1,0) [0|65535] "" BMW_I3
 SG_ ACC_TJA_OLD_E_WORD_B : 24|16@1+ (1,0) [0|65535] "" BMW_I3
 SG_ ACC_TJA_OLD_E_WORD_C : 40|16@1+ (1,0) [0|65535] "" BMW_I3
 SG_ ACC_TJA_OLD_E_WORD_D : 56|16@1+ (1,0) [0|65535] "" BMW_I3
 SG_ ACC_TJA_OLD_CTRL_STATE : 40|16@1+ (1,0) [0|65535] "" BMW_I3
 SG_ ACC_LONG_MAIN_STATE : 40|16@1+ (1,0) [0|65535] "" BMW_I3
 SG_ LAT_DRAFT_087_BYTE0 : 0|8@1+ (1,0) [0|255] "" BMW_I3
 SG_ LAT_DRAFT_087_BYTE1 : 8|8@1+ (1,0) [0|255] "" BMW_I3
 SG_ LAT_DRAFT_087_BYTE2 : 16|8@1+ (1,0) [0|255] "" BMW_I3
 SG_ LAT_DRAFT_087_DIR_CODE : 8|6@1+ (1,0) [0|63] "" BMW_I3
CM_ BO_ 135 "Primary longitudinal/lateral session-state helper, but no longer a single rigid TJA gate. Historical labeling from 000003ff/00000400/00000402 still holds for the older families: manual -> ...22e0e188a205, ACC-only -> ...2228e260a205, older TJA -> ...2228e2604206 / ...20e0e2403206. Newer realdata route 00000006--e6a3e58043 shows additional valid managed-TJA families that do not fit the old 4206-only rule, especially ...20e0e240e201, ...2228e260e201, ...2228e2608202, and ...2228e2408202. Use 135 together with the 60->72 burst behavior when classifying stock lateral context; 135 alone is no longer sufficient to declare ACC-only vs TJA on newer routes. Draft lateral work: on routes 00000401, 00000402, and 00000006, byte1 on this frame is the best current common CAN-only precursor for stock lateral steering activity inside the true lateral windows defined by 0x10D/src0/byte11 == 1.";
CM_ SG_ 135 LAT_DRAFT_087_BYTE0 "Draft helper only. Byte0 behaves like a 16-state phase/counter byte and does not currently decode to steering content.";
CM_ SG_ 135 LAT_DRAFT_087_BYTE1 "Draft helper only. Best current common src0 lateral precursor candidate across routes 401, 402, and 006 when evaluated event-by-event inside the true lateral windows (0x10D/src0/byte11 == 1). Treat as a coded/discrete byte, not an analog steering angle.";
CM_ SG_ 135 LAT_DRAFT_087_BYTE2 "Draft helper only. Byte2 behaves like a rolling phase byte and does not currently decode to steering content.";
CM_ SG_ 135 LAT_DRAFT_087_DIR_CODE "Draft derived direction code from byte1 low 6 bits. Experimental family rule that currently works around 75% on routes 401, 402, and 006: if (old_byte1 & 0x3F) > 44 then steer right, else steer left. This is not yet a final actuator rule.";

BO_ 241 ACC_TJA_OLD_ROUTE_HELPER_F: 17 BMW_I3
 SG_ ACC_TJA_OLD_F_CYCLE : 0|8@1+ (1,0) [0|255] "" BMW_I3
 SG_ ACC_TJA_OLD_F_WORD_A : 8|16@1+ (1,0) [0|65535] "" BMW_I3
 SG_ ACC_TJA_OLD_F_WORD_B : 24|16@1+ (1,0) [0|65535] "" BMW_I3
 SG_ ACC_TJA_OLD_F_WORD_C : 40|16@1+ (1,0) [0|65535] "" BMW_I3
 SG_ ACC_TJA_OLD_F_WORD_D : 56|16@1+ (1,0) [0|65535] "" BMW_I3
 CM_ BO_ 241 "Experimental helper from legacy multi-segment TJA routes 00000054/55/56. Secondary command-related frame retained as raw helper for ACC/TJA comparison work.";

BO_ 250 ACC_TJA_OLD_ROUTE_HELPER_G: 17 BMW_I3
 SG_ ACC_TJA_OLD_G_CYCLE : 0|8@1+ (1,0) [0|255] "" BMW_I3
 SG_ ACC_TJA_OLD_G_WORD_A : 8|16@1+ (1,0) [0|65535] "" BMW_I3
 SG_ ACC_TJA_OLD_G_WORD_B : 24|16@1+ (1,0) [0|65535] "" BMW_I3
 SG_ ACC_TJA_OLD_G_WORD_C : 40|16@1+ (1,0) [0|65535] "" BMW_I3
 SG_ ACC_TJA_OLD_G_WORD_D : 56|16@1+ (1,0) [0|65535] "" BMW_I3
 CM_ BO_ 250 "Experimental helper from legacy multi-segment TJA routes 00000054/55/56. Strong secondary responder during SET/RES/ACC/TJA/speed-stalk windows; kept raw for old-route correlation.";

BO_ 256 ACC_STALK_TJA_CANDIDATE_E: 17 BMW_I3
 SG_ ACC_STALK_TJA_E_WORD_A : 8|16@1+ (1,0) [0|65535] "" BMW_I3
 SG_ ACC_STALK_TJA_E_WORD_B : 24|16@1+ (1,0) [0|65535] "" BMW_I3
 SG_ ACC_STALK_TJA_E_WORD_C : 40|16@1+ (1,0) [0|65535] "" BMW_I3
 CM_ BO_ 256 "Experimental ACC/TJA candidate from TJA and parked command-isolation routes. Small payload frame that changed consistently at SET, RES, ACC, TJA, speed-stalk increment/decrement, distance-button, blinker windows, and ACC off. Good candidate for compact command-state or resume-state signaling.";

BO_ 269 ACC_TJA_OLD_ROUTE_HELPER_H: 17 BMW_I3
 SG_ ACC_TJA_OLD_H_CYCLE : 0|8@1+ (1,0) [0|255] "" BMW_I3
 SG_ ACC_TJA_OLD_H_WORD_A : 8|16@1+ (1,0) [0|65535] "" BMW_I3
 SG_ ACC_TJA_OLD_H_WORD_B : 24|16@1+ (1,0) [0|65535] "" BMW_I3
 SG_ ACC_TJA_OLD_H_WORD_C : 40|16@1+ (1,0) [0|65535] "" BMW_I3
 SG_ ACC_TJA_OLD_H_WORD_D : 56|16@1+ (1,0) [0|65535] "" BMW_I3
 SG_ LAT_TJA_STATE_10D : 88|8@1+ (1,0) [0|255] "" BMW_I3
CM_ BO_ 269 "Experimental helper from legacy multi-segment TJA routes 00000054/55/56. Modern route 00000401 identifies byte11 on this frame as the best current stock lateral-TJA state candidate. EDME/EPS route 00000058 confirms the same byte as a clean TJA managed-window indicator: rlog dat[11] changed 0->1 at 8.373s, 1->0 at 88.359s, 0->1 at 118.868s, and 1->0 at 153.652s, matching the video-marked TJA windows after the camera/rlog offset. EDME/EPS route 00000059 confirms the same rule after ecamera/fcamera alignment: dat[11] entered state 1 at 158.034s and left state 1 at 239.663s, matching the user-verified TJA managed video window. Keep the rest of the payload raw until the full frame is understood.";
CM_ SG_ 269 LAT_TJA_STATE_10D "Best current stock TJA state candidate on frame 0x10D byte11. Current working semantics: 0 = TJA steering button/path not requested; 2 = TJA armed; 3 = TJA longitudinal only active; 1 = TJA managed/lateral-active window confirmed on EDME routes 58/59 and LONG_AND_LATERAL_ACTIVE on previous routes. State 8 marks driver steering override and may also appear when the lead vehicle disappears or becomes too distant for TJA to keep the lateral function engaged. State 16 marks a TJA prerequisite violation or operating-limit violation, for example missing steering-wheel touch or requested curvature outside the valid operating envelope. RX analysis note only: do not use this DBC entry as a TX activation command or synthesize activation from it.";
 VAL_ 269 LAT_TJA_STATE_10D 0 "STEERING_NOT_REQUESTED" 1 "LONG_AND_LATERAL_ACTIVE" 2 "TJA_ARMED" 3 "LONGITUDINAL_ONLY_ACTIVE" 8 "DRIVER_STEERING_OVERRIDE" 16 "PREREQUISITE_OR_OPERATING_LIMIT_VIOLATION";

BO_ 271 ACC_TJA_OLD_ROUTE_HELPER_I: 17 BMW_I3
 SG_ ACC_TJA_OLD_I_CYCLE : 0|8@1+ (1,0) [0|255] "" BMW_I3
 SG_ ACC_TJA_OLD_I_WORD_A : 8|16@1+ (1,0) [0|65535] "" BMW_I3
 SG_ ACC_TJA_OLD_I_WORD_B : 24|16@1+ (1,0) [0|65535] "" BMW_I3
 SG_ ACC_TJA_OLD_I_WORD_C : 40|16@1+ (1,0) [0|65535] "" BMW_I3
 SG_ ACC_TJA_OLD_I_WORD_D : 56|16@1+ (1,0) [0|65535] "" BMW_I3
 CM_ BO_ 271 "Experimental helper from legacy multi-segment TJA routes 00000054/55/56. Src13 frame that follows the same command-family transitions as 135/97/116/112/275, but with weaker consistency.";

BO_ 275 ACC_STALK_TJA_CANDIDATE_F: 17 BMW_I3
 SG_ ACC_STALK_TJA_F_WORD_A : 8|16@1+ (1,0) [0|65535] "" BMW_I3
 SG_ ACC_STALK_TJA_F_WORD_B : 24|16@1+ (1,0) [0|65535] "" BMW_I3
 SG_ ACC_STALK_TJA_F_WORD_C : 40|16@1+ (1,0) [0|65535] "" BMW_I3
 SG_ ACC_STALK_TJA_F_WORD_D : 56|16@1+ (1,0) [0|65535] "" BMW_I3
 SG_ LAT_STOCK_CONFIRM_WORD_A : 8|16@1+ (1,0) [0|65535] "" BMW_I3
 SG_ LAT_STOCK_CONFIRM_WORD_B : 24|16@1+ (1,0) [0|65535] "" BMW_I3
 SG_ LAT_STOCK_CONFIRM_WORD_C : 40|16@1+ (1,0) [0|65535] "" BMW_I3
 SG_ LAT_STOCK_CONFIRM_WORD_D : 56|16@1+ (1,0) [0|65535] "" BMW_I3
 CM_ BO_ 275 "Stock lateral/TJA confirmation helper confirmed on historical routes 00000054 and 00000055 and present on the modern interface in route 000000b3. Historical logs exposed it on src23; modern dual-FlexRay logging exposes the same frame on src1. It is less clean than 112 and 116 but moves consistently with assisted-steering phases and is useful as a third correlation frame.";

BO_ 217 PTCAN_ACCELERATOR_CANDIDATE: 8 BMW_I3
 SG_ ACCEL_RAW_PT_CAN : 0|16@1+ (1,0) [0|65535] "" BMW_I3
 SG_ ACCEL_BYTE_0_PT_CAN : 0|8@1+ (1,0) [0|255] "" BMW_I3
 SG_ ACCEL_BYTE_1_PT_CAN : 8|8@1+ (1,0) [0|255] "" BMW_I3
 SG_ ACCELERATOR_WORD23_PT_CAN : 16|16@1+ (1,0) [0|65535] "" BMW_I3
 SG_ ACCELERATOR_VALUE_PT_CAN : 16|16@1+ (1,-4096) [0|4000] "" BMW_I3
 SG_ ACCELERATOR_I4_COMPAT_PT_CAN : 16|12@1+ (0.000244,0) [0|2047] "" BMW_I3
CM_ BO_ 217 "Confirmed PT-CAN accelerator-family frame. The first 16 bits remain useful as upstream positive/coast long-intent helper, while bytes 2:3 are now confirmed as the driver accelerator analog field on the i3. Current isolated pedal routes show 4096 at release and 8096 at full pedal, giving a clean 0..4000 working span after subtracting 4096.";
CM_ SG_ 217 ACCEL_RAW_PT_CAN "Best current upstream positive/coast long-intent candidate. Cross-route fit against longitudinalPlan.aTarget on 147/148/170/176/177 shows this raw 16-bit field separates positive/coast intent materially better than the downstream helper families that were previously tracked.";
CM_ SG_ 217 ACCELERATOR_WORD23_PT_CAN "Confirmed raw accelerator word from bytes 2:3 on PT-CAN frame 217. Isolated pedal routes show release ~4096 and full pedal ~8096.";
CM_ SG_ 217 ACCELERATOR_VALUE_PT_CAN "Confirmed driver accelerator analog value on PT-CAN frame 217, derived as bytes2:3 minus 4096. Practical observed range: 0 release to 4000 full pedal.";
CM_ SG_ 217 ACCELERATOR_I4_COMPAT_PT_CAN "Legacy i4-compatible helper view of frame 217. Keep as comparison/support only; current i3 long fitting works better on the raw 16-bit field than on this compressed 12-bit projection.";

BO_ 239 PTCAN_CRUISE_BUTTONS_AUX: 8 BMW_I3
 SG_ CRUISE_BTN_AUX_PT_CAN : 0|16@1+ (1,0) [0|65535] "" BMW_I3
 SG_ CRUISE_BTN_AUX_BYTE_0 : 0|8@1+ (1,0) [0|255] "" BMW_I3
 SG_ CRUISE_BTN_AUX_BYTE_1 : 8|8@1+ (1,0) [0|255] "" BMW_I3
 SG_ BRAKE_PEDAL_WORD23_PT_CAN : 16|16@1+ (1,0) [0|65535] "" BMW_I3
 SG_ BRAKE_PEDAL_WORD56_PT_CAN : 40|16@1+ (1,0) [0|65535] "" BMW_I3
 SG_ BRAKE_PEDAL_I4_COMPAT_PT_CAN : 40|12@1+ (-1,3328) [0|3328] "" BMW_I3
CM_ BO_ 239 "PT-CAN auxiliary frame carrying cruise-button support plus a promising friction-brake analog candidate on bytes 2:3 and 5:6. In the latest parked brake-only route, both 16-bit words sit near 32000 at release and decrease monotonically across light, medium, and strong pedal application. This still needs road validation against regen before promotion to production brake logic.";

BO_ 274 PTCAN_BLINKER_STATE_CANDIDATE: 8 BMW_I3
 SG_ BLINKER_STATE_WORD0_PT_CAN : 0|16@1+ (1,0) [0|65535] "" BMW_I3
 SG_ BLINKER_STATE_BYTE_0 : 0|8@1+ (1,0) [0|255] "" BMW_I3
 SG_ BLINKER_STATE_BYTE_2 : 16|8@1+ (1,0) [0|255] "" BMW_I3
 SG_ BLINKER_STATE_BYTE_4 : 32|8@1+ (1,0) [0|255] "" BMW_I3
 SG_ BLINKER_STATE_BYTE_6 : 48|8@1+ (1,0) [0|255] "" BMW_I3
 SG_ BLINKER_STATE_BYTE_7 : 56|8@1+ (1,0) [0|255] "" BMW_I3
CM_ BO_ 274 "Confirmed PT-CAN state helper used for raw blinker-family reverse work. Byte 6 remains useful as a left/right indicator-state discriminator on src 2, but recent parked seatbelt rechecks no longer support byte 7 as a reliable buckle source.";

BO_ 435 PTCAN_SEATBELT_CANDIDATE_A: 8 BMW_I3
 SG_ PTCAN_SEATBELT_BYTE_4_A : 32|8@1+ (1,0) [0|255] "" BMW_I3
CM_ BO_ 435 "Replicated parked seatbelt routes 0000019c and 0000019d show byte 4 tracking buckle state cleanly on src 2: 0x00 latched, 0x04 unlatched. Use together with frame 663 as a cross-check.";

BO_ 481 PTCAN_DRIVER_DOOR_CANDIDATE: 6 BMW_I3
 SG_ DRIVER_DOOR_STATE_BYTE_2 : 16|8@1+ (1,0) [0|255] "" BMW_I3
CM_ BO_ 481 "Confirmed PT-CAN driver-door frame in current CarState. Latest isolated parked door route and the previous two-open-close route both show byte 2 toggling cleanly between 0 (closed) and 1 (open) on src 2.";

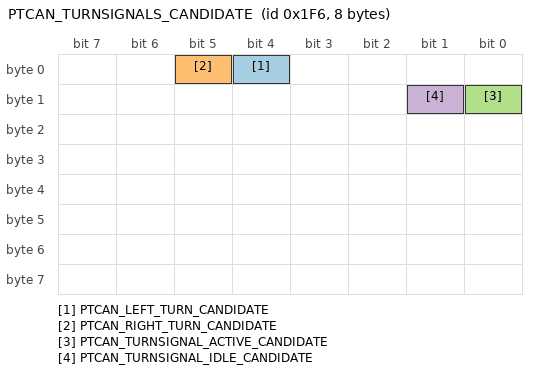
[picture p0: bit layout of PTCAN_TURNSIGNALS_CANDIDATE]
BO_ 502 PTCAN_TURNSIGNALS_CANDIDATE: 8 BMW_I3
 SG_ PTCAN_LEFT_TURN_CANDIDATE : 4|1@1+ (1,0) [0|1] "" BMW_I3
 SG_ PTCAN_RIGHT_TURN_CANDIDATE : 5|1@0+ (1,0) [0|1] "" BMW_I3
 SG_ PTCAN_TURNSIGNAL_ACTIVE_CANDIDATE : 8|1@0+ (1,0) [0|1] "" BMW_I3
 SG_ PTCAN_TURNSIGNAL_IDLE_CANDIDATE : 9|1@0+ (1,0) [0|1] "" BMW_I3
CM_ BO_ 502 "Raw PT-CAN turn-signal helper aligned with the smnogar BMW KCAN DBC. This frame is present on recent i3 routes, but the current i3 parser still prefers frame 274 because it is more robust across the existing captures. Keep 502 as a raw comparison/helper source only for now.";

BO_ 538 PTCAN_BRAKE_PEDAL_CANDIDATE: 3 BMW_I3
 SG_ PTCAN_BRAKE_PEDAL_BYTE_0 : 0|8@1+ (1,0) [0|255] "" BMW_I3
CM_ BO_ 538 "PT-CAN decel / stop-lamp / brake-related helper candidate. It still moves with brake events, but later isolated gas work showed it is not specific enough to be treated as the true pedal source. Keep it as a secondary helper only; brake analog now comes from frame 239 bytes 5:6.";

BO_ 663 PTCAN_SEATBELT_CANDIDATE_B: 7 BMW_I3
 SG_ PTCAN_SEATBELT_BYTE_2_B : 16|8@1+ (1,0) [0|255] "" BMW_I3
CM_ BO_ 663 "Replicated parked seatbelt routes 0000019c and 0000019d show byte 2 tracking buckle state cleanly on src 2: 0xF1 latched, 0xF0 unlatched. Use together with frame 435 as a cross-check.";

BO_ 415 PTCAN_CRUISE_BUTTONS_MAIN: 8 BMW_I3
 SG_ CRUISE_BTN_MAIN_PT_CAN : 16|16@1+ (1,0) [0|65535] "" BMW_I3
 SG_ CRUISE_BTN_MAIN_BYTE_2 : 16|8@1+ (1,0) [0|255] "" BMW_I3
 SG_ CRUISE_BTN_MAIN_BYTE_3 : 24|8@1+ (1,0) [0|255] "" BMW_I3
CM_ BO_ 415 "Primary PT-CAN cruise-button frame. Bytes 2-3 changed cleanly across SET, RES, and distance-button presses with stable idle values, making this the best current main cruise-button source on CAN src 2. Current CarState uses this frame for SET/RES button events; +/- speed and distance semantics remain unresolved.";

BO_ 769 PTCAN_STEERING_WHEEL_COMPANION_CANDIDATE: 7 BMW_I3
 SG_ PTCAN_STEERING_WHEEL_COMPANION_RAW : 16|16@1+ (1,0) [0|65535] "" BMW_I3
 SG_ PTCAN_STEERING_WHEEL_COMPANION_ANGLE_I3_CAL : 16|16@1+ (0.03540,-1159.28) [-720|720] "deg" BMW_I3
CM_ BO_ 769 "Low-rate PT-CAN steering-angle companion on CAN src 2. Treat 770 as the primary live steering-wheel-angle feedback and 769 as a decimated/filtered companion. Current linear scale is centered around raw ~32748 and validated live against about +/-180 deg wheel checkpoints, with raw 37850 ~= +180 deg and raw 27677 ~= -180 deg. Keep the exact OEM semantic split between 769 and 770 open until a dedicated visual steering calibration route confirms the final mapping.";

BO_ 770 PTCAN_STEERING_WHEEL_CANDIDATE: 7 BMW_I3
 SG_ PTCAN_STEERING_WHEEL_RAW : 16|16@1+ (1,0) [0|65535] "" BMW_I3
 SG_ PTCAN_STEERING_WHEEL_ANGLE_I3_CAL : 16|16@1+ (0.03540,-1159.28) [-720|720] "deg" BMW_I3
CM_ BO_ 770 "Primary PT-CAN steering-wheel-angle candidate on CAN src 2. Raw bytes 2-3 still correlate strongest in the full raw scan and remain the best current live steering feedback source on the i3. Current linear scale is centered around raw ~32748 and validated live against about +/-180 deg wheel checkpoints, with raw 37850 ~= +180 deg and raw 27677 ~= -180 deg. Keep the exact OEM signal name and final physical scaling open until a dedicated visual steering calibration route confirms the mapping.";

BO_ 796 PTCAN_BRAKE_PRESSED_CANDIDATE: 8 BMW_I3
 SG_ BRAKE_PRESSED_RAW_PT_CAN : 0|16@1+ (1,0) [0|65535] "" BMW_I3
 SG_ BRAKE_PRESSED_BYTE_0_PT_CAN : 0|8@1+ (1,0) [0|255] "" BMW_I3
 SG_ BRAKE_PRESSED_BYTE_1_PT_CAN : 8|8@1+ (1,0) [0|255] "" BMW_I3
CM_ BO_ 796 "PT-CAN brake/negative-intent helper frame. Byte 1 still separates long negative/coast families and remains useful for longitudinal reverse work, but recent isolated parked brake route 000001a0 shows it is not a reliable standalone brakePressed source.";
CM_ SG_ 796 BRAKE_PRESSED_RAW_PT_CAN "Best current upstream negative/brake long-intent candidate on PT-CAN. Cross-route fit against longitudinalPlan.aTarget shows this frame separates negative intent more cleanly than the downstream helper families that were previously tracked, especially when combined with byte1.";
CM_ SG_ 796 BRAKE_PRESSED_BYTE_1_PT_CAN "Strongest current coarse negative/brake discriminator. Current pragmatic managed-mode negative bucket sits near byte1 ~13, while coast/positive windows stay near the idle range (~0x20..0x2E).";

BO_ 1017 PTCAN_GEAR_CANDIDATE: 8 BMW_I3
 SG_ PTCAN_GEAR_RAW_CANDIDATE : 50|3@0+ (1,0) [0|7] "" BMW_I3
 SG_ PTCAN_GEAR_I4_COMPAT : 50|3@0+ (1,0) [0|7] "" BMW_I3
CM_ BO_ 1017 "Raw PT-CAN gear helper aligned with the smnogar BMW KCAN DBC. This frame is present on recent i3 routes, but the current captures do not separate all gear states cleanly enough to replace the existing drive-state logic. Keep it as a raw/helper source for future gear validation only.";
